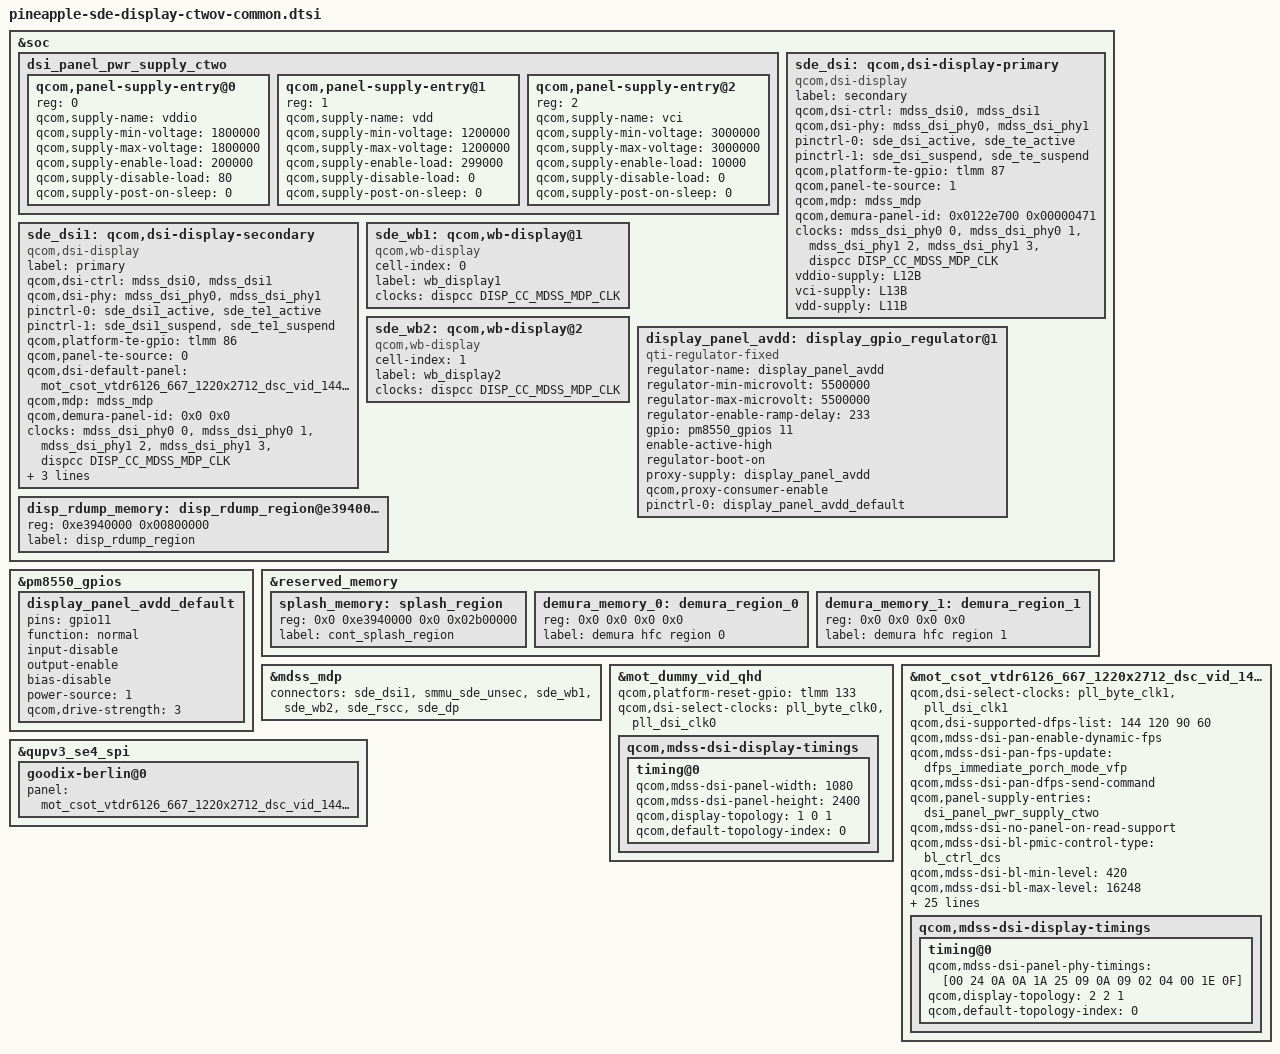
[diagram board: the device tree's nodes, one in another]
/* This is derivated from qcom pineapple-sde-display-mtp.dtsi */

#include "pineapple-sde.dtsi"
#include "pineapple-sde-display-pinctrl.dtsi"
#include <dt-bindings/clock/qcom,dispcc-pineapple.h>
#include "dsi-panel-mot-dummy-qhd-video.dtsi"
#include "dsi-panel-mot-csot-vtdr6126-667-1220x2712-dsc-video-144hz-common-v0.dtsi"
#include "dsi-panel-mot-csot-vtdr6126-667-1220x2712-dsc-video-144hz-common-v0-lhbm.dtsi"
&soc {
	dsi_panel_pwr_supply_ctwo: dsi_panel_pwr_supply_ctwo {
		#address-cells = <1>;
		#size-cells = <0>;

		qcom,panel-supply-entry@0 {
			reg = <0>;
			qcom,supply-name = "vddio";
			qcom,supply-min-voltage = <1800000>;
			qcom,supply-max-voltage = <1800000>;
			qcom,supply-enable-load = <200000>;
			qcom,supply-disable-load = <80>;
			qcom,supply-post-on-sleep = <0>;
		};

		qcom,panel-supply-entry@1 {
			reg = <1>;
			qcom,supply-name = "vdd";
			qcom,supply-min-voltage = <1200000>;
			qcom,supply-max-voltage = <1200000>;
			qcom,supply-enable-load = <299000>;
			qcom,supply-disable-load = <0>;
			qcom,supply-post-on-sleep = <0>;
		};

		qcom,panel-supply-entry@2 {
			reg = <2>;
			qcom,supply-name = "vci";
			qcom,supply-min-voltage = <3000000>;
			qcom,supply-max-voltage = <3000000>;
			qcom,supply-enable-load = <10000>;
			qcom,supply-disable-load = <0>;
			qcom,supply-post-on-sleep = <0>;
		};
	};
	sde_dsi: qcom,dsi-display-primary {
		compatible = "qcom,dsi-display";
		label = "secondary";

		qcom,dsi-ctrl = <&mdss_dsi0 &mdss_dsi1>;
		qcom,dsi-phy = <&mdss_dsi_phy0 &mdss_dsi_phy1>;

		pinctrl-names = "panel_active", "panel_suspend";
		pinctrl-0 = <&sde_dsi_active &sde_te_active>;
		pinctrl-1 = <&sde_dsi_suspend &sde_te_suspend>;

		qcom,platform-te-gpio = <&tlmm 87 0>;
		qcom,panel-te-source = <1>;

		qcom,mdp = <&mdss_mdp>;

		qcom,demura-panel-id = <0x0122e700 0x00000471>;
	};

	sde_dsi1: qcom,dsi-display-secondary {
		compatible = "qcom,dsi-display";
		label = "primary";

		qcom,dsi-ctrl = <&mdss_dsi0 &mdss_dsi1>;
		qcom,dsi-phy = <&mdss_dsi_phy0 &mdss_dsi_phy1>;

		pinctrl-names = "panel_active", "panel_suspend";
		pinctrl-0 = <&sde_dsi1_active &sde_te1_active>;
		pinctrl-1 = <&sde_dsi1_suspend &sde_te1_suspend>;

		qcom,platform-te-gpio = <&tlmm 86 0>;
		qcom,panel-te-source = <0>;
		qcom,dsi-default-panel = <&dsi_vtdr6130_amoled_cmd>;
		qcom,mdp = <&mdss_mdp>;
		qcom,demura-panel-id = <0x0 0x0>;
	};

};
&pm8550_gpios {
	display_panel_avdd_default: display_panel_avdd_default {
		pins = "gpio11";
		function = "normal";
		input-disable;
		output-enable;
		bias-disable;
		power-source = <1>;
		qcom,drive-strength = <3>;
	};
};

&soc {
	sde_wb1: qcom,wb-display@1 {
		compatible = "qcom,wb-display";
		cell-index = <0>;
		label = "wb_display1";
		clocks = <&dispcc DISP_CC_MDSS_MDP_CLK>;
		clock-names = "mdp_core_clk";
	};

	sde_wb2: qcom,wb-display@2 {
		compatible = "qcom,wb-display";
		cell-index = <1>;
		label = "wb_display2";
		clocks = <&dispcc DISP_CC_MDSS_MDP_CLK>;
		clock-names = "mdp_core_clk";
	};

	display_panel_avdd: display_gpio_regulator@1 {
		compatible = "qti-regulator-fixed";
		regulator-name = "display_panel_avdd";
		regulator-min-microvolt = <5500000>;
		regulator-max-microvolt = <5500000>;
		regulator-enable-ramp-delay = <233>;
		gpio = <&pm8550_gpios 11 0>;
		enable-active-high;
		regulator-boot-on;
		proxy-supply = <&display_panel_avdd>;
		qcom,proxy-consumer-enable;
		pinctrl-names = "default";
		pinctrl-0 = <&display_panel_avdd_default>;
	};

	disp_rdump_memory: disp_rdump_region@e3940000 {
		reg = <0xe3940000 0x00800000>;
		label = "disp_rdump_region";
	};
};

&reserved_memory {
	splash_memory: splash_region {
		reg = <0x0 0xe3940000 0x0 0x02b00000>;
		label = "cont_splash_region";
	};
	/*
	 * Demura memory regions are to be commented out if
	 * feature not in use.
	 */
	demura_memory_0: demura_region_0 {
		reg = <0x0 0x0 0x0 0x0>;
		label = "demura hfc region 0";
	};

	demura_memory_1: demura_region_1 {
		reg = <0x0 0x0 0x0 0x0>;
		label = "demura hfc region 1";
	};
};

&sde_dsi {
	clocks = <&mdss_dsi_phy0 0>,
		 <&mdss_dsi_phy0 1>,
		 <&mdss_dsi_phy1 2>,
		 <&mdss_dsi_phy1 3>,
		 /*
		  * Currently the dsi clock handles are under the dsi
		  * controller DT node. As soon as the controller probe
		  * finishes, the dispcc sync state can get called before
		  * the dsi_display probe potentially disturbing the clock
		  * votes for cont_splash use case. Hence we are no longer
		  * protected by the component model in this case against the
		  * disp cc sync state getting triggered after the dsi_ctrl
		  * probe. To protect against this incorrect sync state trigger
		  * add this dummy MDP clk vote handle to the dsi_display
		  * DT node. Since the dsi_display driver does not parse
		  * MDP clock nodes, no actual vote shall be added and this
		  * change is done just to satisfy sync state requirements.
		  */
		 <&dispcc DISP_CC_MDSS_MDP_CLK>;
	clock-names = "pll_byte_clk0", "pll_dsi_clk0",
		      "pll_byte_clk1", "pll_dsi_clk1",
		      "mdp_core_clk";
	vddio-supply = <&L12B>;
	vci-supply = <&L13B>;
	vdd-supply = <&L11B>;
};

&sde_dsi1 {
	clocks = <&mdss_dsi_phy0 0>,
		 <&mdss_dsi_phy0 1>,
		 <&mdss_dsi_phy1 2>,
		 <&mdss_dsi_phy1 3>,
		 /*
		  * Currently the dsi clock handles are under the dsi
		  * controller DT node. As soon as the controller probe
		  * finishes, the dispcc sync state can get called before
		  * the dsi_display probe potentially disturbing the clock
		  * votes for cont_splash use case. Hence we are no longer
		  * protected by the component model in this case against the
		  * disp cc sync state getting triggered after the dsi_ctrl
		  * probe. To protect against this incorrect sync state trigger
		  * add this dummy MDP clk vote handle to the dsi_display
		  * DT node. Since the dsi_display driver does not parse
		  * MDP clock nodes, no actual vote shall be added and this
		  * change is done just to satisfy sync state requirements.
		  */
		 <&dispcc DISP_CC_MDSS_MDP_CLK>;
	clock-names = "pll_byte_clk0", "pll_dsi_clk0",
		      "pll_byte_clk1", "pll_dsi_clk1",
		      "mdp_core_clk";
	vddio-supply = <&L12B>;
	vci-supply = <&L13B>;
	vdd-supply = <&L11B>;
};

&mdss_mdp {
	connectors = < &sde_dsi1 &smmu_sde_unsec &sde_wb1 &sde_wb2 &sde_rscc &sde_dp>;
};

&sde_dsi1 {
	qcom,dsi-default-panel = <&mot_csot_vtdr6126_667_1220x2712_dsc_vid_144hz>;
};

&mot_dummy_vid_qhd {
	qcom,mdss-dsi-display-timings {
                timing@0{
			qcom,mdss-dsi-panel-width = <1080>;
			qcom,mdss-dsi-panel-height = <2400>;
		};
	};
};

//&L11B {
//       regulator-min-microvolt = <1230000>;
//       regulator-max-microvolt = <1280000>;
//       qcom,init-voltage = <1250000>;
//};

&mot_csot_vtdr6126_667_1220x2712_dsc_vid_144hz {
	qcom,dsi-select-clocks = "pll_byte_clk1", "pll_dsi_clk1";

	qcom,dsi-supported-dfps-list = <144 120 90 60>;
	qcom,mdss-dsi-pan-enable-dynamic-fps;
	qcom,mdss-dsi-pan-fps-update = "dfps_immediate_porch_mode_vfp";
	qcom,mdss-dsi-pan-dfps-send-command;

	//qcom,dsi-dyn-clk-enable;

	qcom,panel-supply-entries = <&dsi_panel_pwr_supply_ctwo>;
	qcom,mdss-dsi-no-panel-on-read-support;
	qcom,mdss-dsi-bl-pmic-control-type = "bl_ctrl_dcs";
	qcom,mdss-dsi-bl-min-level = <420>;//
	qcom,mdss-dsi-bl-max-level = <16248>;
	qcom,mdss-dsi-bl-default-level = <10230>;
	qcom,mdss-brightness-max-level = <16248>;
	qcom,platform-reset-gpio = <&tlmm 133 0>;
	qcom,bl-dsc-cmd-state = "dsi_hs_mode";
	qcom,mdss-dsi-bl-inverted-dbv;
	qcom,mdss-dsi-bl-is-exponent;
	qcom,mdss-dsi-bl-double-write;

	qcom,mdss-dsi-panel-hdr-enabled;//
	qcom,mdss-dsi-panel-hdr-color-primaries = <14950 15750 34000
	        16000 13000 35500 7000 2500>;
	qcom,mdss-dsi-panel-peak-brightness = <15000000>;
	qcom,mdss-dsi-panel-blackness-level = <1>;

	qcom,mdss-dsi-panel-status-check-mode = "reg_read";
	qcom,mdss-dsi-panel-status-command = [06 01 00 01 00 00 01 66];
	qcom,mdss-dsi-panel-status-command-state = "dsi_lp_mode";
	qcom,mdss-dsi-panel-status-value = <0 0 0>;
	qcom,mdss-dsi-panel-status-read-length = <3>;
	qcom,esd-check-enabled;

	qcom,cellid-read-enabled;//
	qcom,mdss-dsi-panel-cellid-read-length = <23>;
	qcom,mdss-dsi-panel-cellid-command = [06 01 00 01 00 00 01 5A];

	qcom,mdss-dsi-display-timings {
		timing@0 {
			//qcom,mdss-dsi-panel-clockrate = <1095000000>;
			qcom,mdss-dsi-panel-phy-timings = [00 24 0A 0A 1A 25 09
				0A 09 02 04 00 1E 0F];
			qcom,display-topology = <2 2 1>;
			qcom,default-topology-index = <0>;
		};
	};
};

&mot_dummy_vid_qhd {
	qcom,platform-reset-gpio = <&tlmm 133 0>;

	qcom,dsi-select-clocks = "pll_byte_clk0", "pll_dsi_clk0";
	qcom,mdss-dsi-display-timings {
		timing@0 {
			qcom,display-topology = <1 0 1>;
			qcom,default-topology-index = <0>;
		};
	};
};

&qupv3_se4_spi {
    goodix-berlin@0 {
        panel = <&mot_csot_vtdr6126_667_1220x2712_dsc_vid_144hz>;
    };
};
